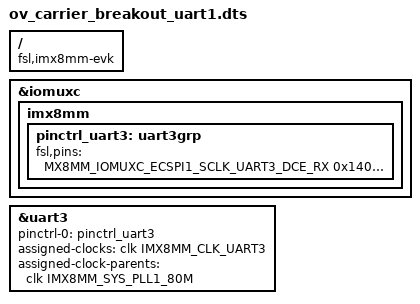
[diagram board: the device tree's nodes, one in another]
/**
 * Portenta-M8 dtb overlay file
 * Arduino 2021
 * Enable UART1 on Arduino Breakout carrier board
 */

/dts-v1/;
/plugin/;

#include <dt-bindings/clock/imx8mm-clock.h>
#include "imx8mm-pinfunc.h"

/ {
	compatible = "fsl,imx8mm-evk", "fsl,imx8mm";

	fragment@0 {
		target = <&iomuxc>;
		__overlay__ {
			imx8mm {
				pinctrl_uart3: uart3grp {
					fsl,pins = <
						MX8MM_IOMUXC_ECSPI1_SCLK_UART3_DCE_RX     0x140
						MX8MM_IOMUXC_ECSPI1_MOSI_UART3_DCE_TX     0x140
						MX8MM_IOMUXC_ECSPI1_SS0_UART3_DCE_RTS_B   0x140
						MX8MM_IOMUXC_ECSPI1_MISO_UART3_DCE_CTS_B  0x140
					>;
				};
			};
		};
	};

	fragment@1 {
		target = <&uart3>;
		__overlay__ {
			pinctrl-names = "default";
			pinctrl-0 = <&pinctrl_uart3>;
			assigned-clocks = <&clk IMX8MM_CLK_UART3>;
			assigned-clock-parents = <&clk IMX8MM_SYS_PLL1_80M>;
			/* fsl,uart-has-rtscts; */
			status = "okay";
		};
	};
};
